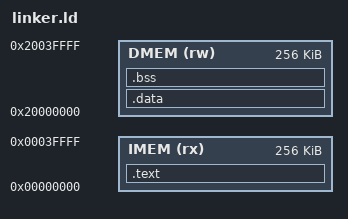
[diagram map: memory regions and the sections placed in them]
ENTRY(_start)

MEMORY
{
    IMEM (rx) : ORIGIN = 0x00000000, LENGTH = 256K
    DMEM (rw) : ORIGIN = 0x20000000, LENGTH = 256K
}

SECTIONS
{
    .text : {
        *(.text*)
        *(.rodata*)
    } > IMEM

    .data : {
        *(.data*)
        *(.sdata*)
    } > DMEM

    .bss : {
        *(.bss*)
        *(.sbss*)
        *(COMMON)
    } > DMEM
}
